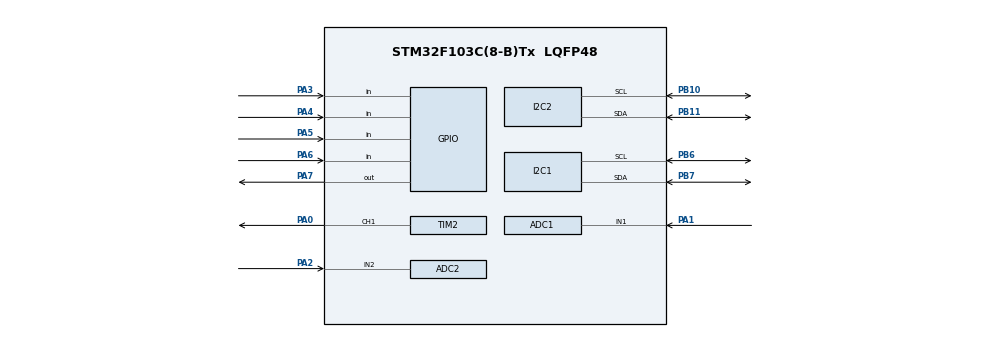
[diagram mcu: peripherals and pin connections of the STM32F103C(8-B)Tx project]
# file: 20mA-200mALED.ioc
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ADC1.Channel-0\#ChannelRegularConversion=ADC_CHANNEL_1
ADC1.NbrOfConversionFlag=1
ADC1.master=1
ADC2.Channel-0\#ChannelRegularConversion=ADC_CHANNEL_2
ADC2.NbrOfConversionFlag=1
ADC2.Rank-0\#ChannelRegularConversion=1
ADC2.SamplingTime-0\#ChannelRegularConversion=ADC_SAMPLETIME_1CYCLE_5
Mcu.Family=STM32F1
Mcu.Name=STM32F103C(8-B)Tx
Mcu.Package=LQFP48
NVIC.PriorityGroup=NVIC_PRIORITYGROUP_4
PA0-WKUP.Signal=S_TIM2_CH1_ETR
PA1.Signal=ADCx_IN1
PA13.Mode=Serial_Wire
PA13.Signal=SYS_JTMS-SWDIO
PA14.Mode=Serial_Wire
PA14.Signal=SYS_JTCK-SWCLK
PA2.Signal=ADCx_IN2
PA3.Signal=GPIO_Input
PA4.Signal=GPIO_Input
PA5.Signal=GPIO_Input
PA6.Signal=GPIO_Input
PA7.Signal=GPIO_Output
PB10.Mode=I2C
PB10.Signal=I2C2_SCL
PB11.Mode=I2C
PB11.Signal=I2C2_SDA
PB6.Mode=I2C
PB6.Signal=I2C1_SCL
PB7.Mode=I2C
PB7.Signal=I2C1_SDA
PD0-OSC_IN.Mode=HSE-External-Oscillator
PD0-OSC_IN.Signal=RCC_OSC_IN
PD1-OSC_OUT.Mode=HSE-External-Oscillator
PD1-OSC_OUT.Signal=RCC_OSC_OUT
ProjectManager.HeapSize=0x200
ProjectManager.StackSize=0x400
ProjectManager.TargetToolchain=MDK-ARM V5.32
RCC.APB1CLKDivider=RCC_HCLK_DIV2
RCC.APB1Freq_Value=4000000
RCC.APB1TimFreq_Value=8000000
RCC.APB2Freq_Value=8000000
SH.ADCx_IN1.0=ADC1_IN1,IN1
SH.ADCx_IN2.0=ADC2_IN2,IN2
SH.S_TIM2_CH1_ETR.0=TIM2_CH1,PWM Generation1 CH1
TIM2.Channel-PWM\ Generation1\ CH1=TIM_CHANNEL_1
TIM2.Period=999
TIM2.Prescaler=71
board=custom

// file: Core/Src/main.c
/* USER CODE BEGIN Header */
/**
  ******************************************************************************
  * @file           : main.c
  * @brief          : Main program body
  *   STM32F103C8 · 5V 输入输出恒流 LED（20mA~200mA）
  *   · PWM 调光（TIM2_CH1/PA0）     · ADC 实时采样电流（ADC2/PA2）
  *   · 恒流闭环（PI 稳定到目标电流）· 自动光控（光敏 ADC1/PA1）· 定时开关
  *   · 3 键：PB12 开关 / PB13 手动↔自动光控 / PB14 短按档位·长按定时
  *
  *   烧录后默认：输出开、恒流闭环、目标 200mA → LED 直接亮。
  *
  *   【最小点亮测试】若灯不亮，把下面 DEBUG_FORCE_PWM_ON 改为 1 重新编译烧录，
  *   此时主循环只输出固定 PWM(800)，绕过所有按键/恒流逻辑：
  *     - 灯亮     → 硬件 OK，问题在按键/逻辑代码
  *     - 灯仍不亮 → 检查 PA0 PWM 波形 / 恒流电路 / LED 接线
  ******************************************************************************
  */
/* USER CODE END Header */

#include "main.h"
#include "adc.h"
#include "i2c.h"
#include "tim.h"
#include "gpio.h"

/* USER CODE BEGIN Includes */
#include "bsp_pwm.h"
#include "bsp_adc.h"
#include "bsp_light.h"
#include "bsp_key.h"
#include "bsp_led.h"
#include "key_app.h"
/* USER CODE END Includes */

/* USER CODE BEGIN PD */

/* 最小点亮测试开关：1=主循环只输出固定 PWM，用于排查硬件；0=正常运行 */
#define DEBUG_FORCE_PWM_ON   0u

/* USER CODE END PD */

void SystemClock_Config(void);

int main(void)
{
  /* MCU Configuration--------------------------------------------------------*/
  HAL_Init();

  /* Configure the system clock */
  SystemClock_Config();

  /* Initialize all configured peripherals */
  MX_GPIO_Init();
  MX_ADC1_Init();
  MX_ADC2_Init();
  MX_I2C1_Init();
  MX_I2C2_Init();
  MX_TIM2_Init();

  /* 开启 TIM2_CH1(PA0) 的 PWM 输出 */
  HAL_TIM_PWM_Start(&htim2, TIM_CHANNEL_1);

  /* 6 键按键处理初始化（内部会初始化按键引脚并默认输出 50% 亮度） */
  KEY_AppInit();

  /* Infinite loop */
  while (1)
  {
    /* 最小点亮测试：强制固定 PWM，绕过全部按键/恒流逻辑 */
    if (DEBUG_FORCE_PWM_ON)
    {
      PWM_SetDuty(800u);
      HAL_Delay(10u);
      continue;
    }

    /* 正常运行：5ms 扫键 + 按键动作 + 光控 + 定时 + 恒流闭环 */
    KEY_AppHandle();
  }
}

void SystemClock_Config(void)
{
  RCC_OscInitTypeDef RCC_OscInitStruct = {0};
  RCC_ClkInitTypeDef RCC_ClkInitStruct = {0};
  RCC_PeriphCLKInitTypeDef PeriphClkInit = {0};

  /** Initializes the RCC Oscillators according to the specified parameters
  * in the RCC_OscInitTypeDef structure.
  */
  RCC_OscInitStruct.OscillatorType = RCC_OSCILLATORTYPE_HSI;
  RCC_OscInitStruct.HSIState = RCC_HSI_ON;
  RCC_OscInitStruct.HSICalibrationValue = RCC_HSICALIBRATION_DEFAULT;
  RCC_OscInitStruct.PLL.PLLState = RCC_PLL_NONE;
  if (HAL_RCC_OscConfig(&RCC_OscInitStruct) != HAL_OK)
  {
    Error_Handler();
  }

  /** Initializes the CPU, AHB and APB buses clocks
  */
  RCC_ClkInitStruct.ClockType = RCC_CLOCKTYPE_HCLK|RCC_CLOCKTYPE_SYSCLK
                              |RCC_CLOCKTYPE_PCLK1|RCC_CLOCKTYPE_PCLK2;
  RCC_ClkInitStruct.SYSCLKSource = RCC_SYSCLKSOURCE_HSI;
  RCC_ClkInitStruct.AHBCLKDivider = RCC_SYSCLK_DIV1;
  RCC_ClkInitStruct.APB1CLKDivider = RCC_HCLK_DIV2;
  RCC_ClkInitStruct.APB2CLKDivider = RCC_HCLK_DIV1;

  if (HAL_RCC_ClockConfig(&RCC_ClkInitStruct, FLASH_LATENCY_0) != HAL_OK)
  {
    Error_Handler();
  }
  PeriphClkInit.PeriphClockSelection = RCC_PERIPHCLK_ADC;
  PeriphClkInit.AdcClockSelection = RCC_ADCPCLK2_DIV2;
  if (HAL_RCCEx_PeriphCLKConfig(&PeriphClkInit) != HAL_OK)
  {
    Error_Handler();
  }
}

void Error_Handler(void)
{
  __disable_irq();
  while (1)
  {
  }
}
